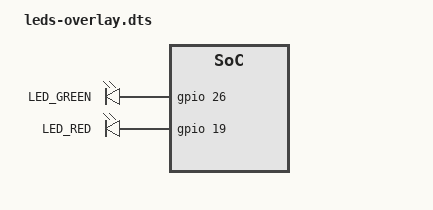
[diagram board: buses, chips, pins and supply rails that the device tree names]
/dts-v1/;
/plugin/;

/ {
	fragment@0 {
/*
		target = <&gpio>;
		__overlay__ {
			led_Green: led_Green {
				brcm,pins = <26>;
				brcm,function = <0>;
				brcm,pull = <2>;
			};
			led_Red: led_Red {
				brcm,pins = <19>;
				brcm,function = <0>;
				brcm,pull = <2>;
			};
		};
	};

	fragment@1 {
*/
		target = <&leds>;
		__overlay__ {
			status = "okay";
			ledGreen: ledGreen {
				label = "LED_GREEN";
				gpios = <&gpio 26 0>;
				linux,default-trigger = "heartbeat";
			};
			ledRed: ledRed {
				label = "LED_RED";
				gpios = <&gpio 19 0>;
				linux,default-trigger = "timer";
			};
		};
	};
};


